# flash register map
Vendor: Texas Instruments
Peripheral module from a debugger description file (folder sc4ce290ncpz).
Registers are 32-bit, read-write, no defined reset value unless marked. A register's access mark holds for its fields unless they carry their own. Offsets are as the file gives them; lines under a group give offsets from that group; [hi:lo] are bit positions; {n}, {i} and the like mark numbered series; 'fields as' and 'values as' point back to an identical list; <NAME> marks a mode.

## FLASH_CTRL — FLASH register offsets
0x00 FLASH_FMA — Flash Memory Address
  [19:0] FLASH_FMA_OFFSET — Address Offset
0x04 FLASH_FMD — Flash Memory Data
  [31:0] FLASH_FMD_DATA — Data Value
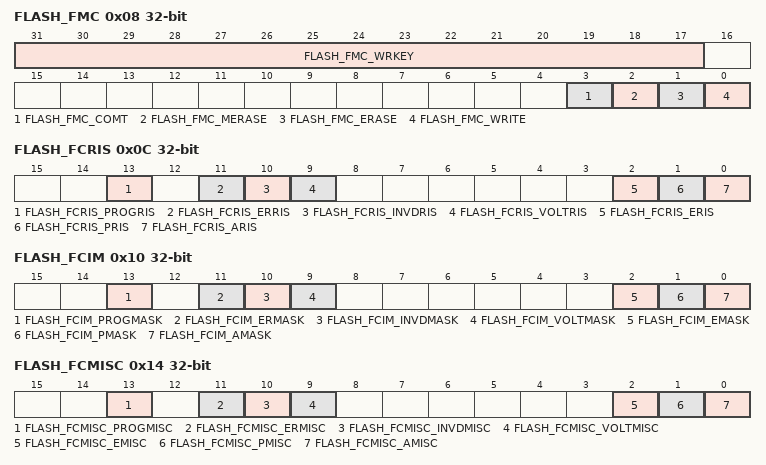
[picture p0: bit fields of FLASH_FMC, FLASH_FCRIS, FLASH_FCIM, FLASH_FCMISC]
0x08 FLASH_FMC — Flash Memory Control
  [31:17] FLASH_FMC_WRKEY — FLASH write key
  [3] FLASH_FMC_COMT — Commit Register Value
  [2] FLASH_FMC_MERASE — Mass Erase Flash Memory
  [1] FLASH_FMC_ERASE — Erase a Page of Flash Memory
  [0] FLASH_FMC_WRITE — Write a Word into Flash Memory
0x0C FLASH_FCRIS ro — Flash Controller Raw Interrupt Status
  [13] FLASH_FCRIS_PROGRIS — Program Verify Error Raw Interrupt Status
  [11] FLASH_FCRIS_ERRIS — Erase Verify Error Raw Interrupt Status
  [10] FLASH_FCRIS_INVDRIS — Invalid Data Raw Interrupt Status
  [9] FLASH_FCRIS_VOLTRIS — Pump Voltage Raw Interrupt Status
  [2] FLASH_FCRIS_ERIS — EEPROM Raw Interrupt Status
  [1] FLASH_FCRIS_PRIS — Programming Raw Interrupt Status
  [0] FLASH_FCRIS_ARIS — Access Raw Interrupt Status
0x10 FLASH_FCIM — Flash Controller Interrupt Mask
  [13] FLASH_FCIM_PROGMASK — PROGVER Interrupt Mask
  [11] FLASH_FCIM_ERMASK — ERVER Interrupt Mask
  [10] FLASH_FCIM_INVDMASK — Invalid Data Interrupt Mask
  [9] FLASH_FCIM_VOLTMASK — VOLT Interrupt Mask
  [2] FLASH_FCIM_EMASK — EEPROM Interrupt Mask
  [1] FLASH_FCIM_PMASK — Programming Interrupt Mask
  [0] FLASH_FCIM_AMASK — Access Interrupt Mask
0x14 FLASH_FCMISC — Flash Controller Masked Interrupt Status and Clear
  [13] FLASH_FCMISC_PROGMISC — PROGVER Masked Interrupt Status and Clear
  [11] FLASH_FCMISC_ERMISC — ERVER Masked Interrupt Status and Clear
  [10] FLASH_FCMISC_INVDMISC — Invalid Data Masked Interrupt Status and Clear
  [9] FLASH_FCMISC_VOLTMISC — VOLT Masked Interrupt Status and Clear
  [2] FLASH_FCMISC_EMISC — EEPROM Masked Interrupt Status and Clear
  [1] FLASH_FCMISC_PMISC — Programming Masked Interrupt Status and Clear
  [0] FLASH_FCMISC_AMISC — Access Masked Interrupt Status and Clear
0x20 FLASH_FMC2 — Flash Memory Control 2
  [0] FLASH_FMC2_WRBUF — Buffered Flash Memory Write
0x30 FLASH_FWBVAL — Flash Write Buffer Valid
  [31:0] FLASH_FWBVAL_FWB — Flash Memory Write Buffer
0x3C FLASH_FLPEKEY — Flash Program/Erase Key
  [15:0] FLASH_FLPEKEY_PEKEY — Key Value
0x100 FLASH_FWBN — Flash Write Buffer n
  [31:0] FLASH_FWBN_DATA — Data
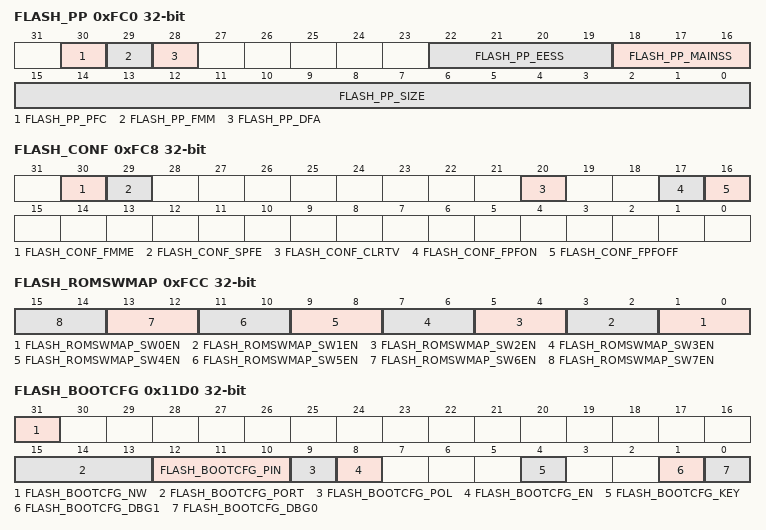
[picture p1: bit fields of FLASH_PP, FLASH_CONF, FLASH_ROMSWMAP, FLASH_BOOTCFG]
0xFC0 FLASH_PP ro — Flash Peripheral Properties
  [30] FLASH_PP_PFC — Prefetch Buffer Mode
  [29] FLASH_PP_FMM — Flash Mirror Mode
  [28] FLASH_PP_DFA — DMA Flash Access
  [22:19] FLASH_PP_EESS — EEPROM Sector Size of the physical bank
    0=FLASH_PP_EESS_1KB (1 KB); 1=FLASH_PP_EESS_2KB (2 KB); 2=FLASH_PP_EESS_4KB (4 KB); 3=FLASH_PP_EESS_8KB (8 KB)
  [18:16] FLASH_PP_MAINSS — Flash Sector Size of the physical bank
    0=FLASH_PP_MAINSS_1KB (1 KB); 1=FLASH_PP_MAINSS_2KB (2 KB); 2=FLASH_PP_MAINSS_4KB (4 KB); 3=FLASH_PP_MAINSS_8KB (8 KB); 4=FLASH_PP_MAINSS_16KB (16 KB)
  [15:0] FLASH_PP_SIZE — Flash Size
    0x1FF=FLASH_PP_SIZE_1MB (1024 KB of Flash)
0xFC4 FLASH_SSIZE ro — SRAM Size
  [15:0] FLASH_SSIZE_SIZE
    0x3FF=FLASH_SSIZE_SIZE_256KB (256 KB of SRAM)
0xFC8 FLASH_CONF — Flash Configuration Register
  [30] FLASH_CONF_FMME — Flash Mirror Mode Enable
  [29] FLASH_CONF_SPFE — Single Prefetch Mode Enable
  [20] FLASH_CONF_CLRTV — Clear Valid Tags
  [17] FLASH_CONF_FPFON — Force Prefetch On
  [16] FLASH_CONF_FPFOFF — Force Prefetch Off
0xFCC FLASH_ROMSWMAP ro — ROM Software Map
  [2n+1:2n] FLASH_ROMSWMAP_SW{n}EN (n=0..7) — ROM SW Region {n} Availability
    0=FLASH_ROMSWMAP_SW{n}EN_NOTVIS (Software region not available to the core); 1=FLASH_ROMSWMAP_SW{n}EN_CORE (Region available to core)
0xFD0 FLASH_DMASZ — Flash DMA Address Size
  [17:0] FLASH_DMASZ_SIZE — uDMA-accessible Memory Size
0xFD4 FLASH_DMAST — Flash DMA Starting Address
  [28:11] FLASH_DMAST_ADDR — Contains the starting address of the flash region accessible by uDMA if the FLASHPP register DFA bit is set
0x10D4 FLASH_RVP — Reset Vector Pointer
  [31:0] FLASH_RVP_RV — Reset Vector Pointer Address
0x11D0 FLASH_BOOTCFG ro — Boot Configuration
  [31] FLASH_BOOTCFG_NW — Not Written
  [15:13] FLASH_BOOTCFG_PORT — Boot GPIO Port
    0=FLASH_BOOTCFG_PORT_A (Port A); 1=FLASH_BOOTCFG_PORT_B (Port B); 2=FLASH_BOOTCFG_PORT_C (Port C); 3=FLASH_BOOTCFG_PORT_D (Port D); 4=FLASH_BOOTCFG_PORT_E (Port E); 5=FLASH_BOOTCFG_PORT_F (Port F); 6=FLASH_BOOTCFG_PORT_G (Port G); 7=FLASH_BOOTCFG_PORT_H (Port H)
  [12:10] FLASH_BOOTCFG_PIN — Boot GPIO Pin
    {v}=Pin {v} (v=0..7)
  [9] FLASH_BOOTCFG_POL — Boot GPIO Polarity
  [8] FLASH_BOOTCFG_EN — Boot GPIO Enable
  [4] FLASH_BOOTCFG_KEY — KEY Select
  [1] FLASH_BOOTCFG_DBG1 — Debug Control 1
  [0] FLASH_BOOTCFG_DBG0 — Debug Control 0
{0x11E0+4i} FLASH_USERREG{i} (i=0..3) — User Register {i}
  [31:0] FLASH_USERREG{i}_DATA — User Data
{0x1200+4i} FLASH_FMPRE{i} access not given (i=0..7) — Flash Memory Protection Read Enable {i}
{0x1200+4i} FLASH_FMPRE{i} (i=8..15) — Flash Memory Protection Read Enable {i}
  [31:0] FLASH_FMPRE{i}_READ_ENABLE — Flash Read Enable
{0x1400+4i} FLASH_FMPPE{i} access not given (i=0..7) — Flash Memory Protection Program Enable {i}
{0x1400+4i} FLASH_FMPPE{i} (i=8..15) — Flash Memory Protection Program Enable {i}
  [31:0] FLASH_FMPPE{i}_PROG_ENABLE — Flash Programming Enable
